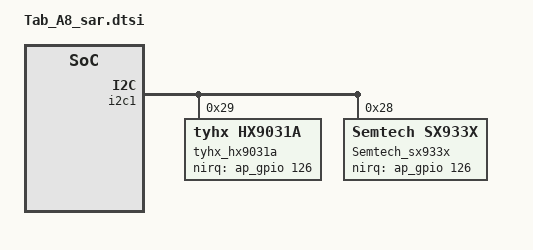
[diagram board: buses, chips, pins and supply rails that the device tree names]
/* I2C device */
&i2c1{
/*Tab A8 code for SR-AX6300-01-81 by mayuhang at 2021/8/12 start*/
    tyhx_hx9031a@29 {
        compatible = "tyhx,hx9031a";
        reg = <0x29>;
        interrupt-parent = <&ap_gpio>;
        //interrupts = <126 0>;
        tyhx,nirq-gpio = <&ap_gpio 126 0x00>;
        tyhx,channel-flag = <0x07>;
    };
/*Tab A8 code for SR-AX6300-01-81 by mayuhang at 2021/8/12 end*/
/*Tab A8 code for SR-AX6300-01-66|AX6300DEV-4155 by mayuhang|lichang at 2022/11/29 start*/
    Semtech_sx933x@28 {
        compatible = "Semtech,sx933x";
        reg = <0x28>;
        interrupt-parent = <&ap_gpio>;
        //interrupts = <126 0>;
        Semtech,nirq-gpio = <&ap_gpio 126 0x00>;
        /*use PH3/4 as the reference sensor
        set it to 0xff if the ref-phases-x is not used*/
        Semtech,ref-phases-a = <0>;
        Semtech,ref-phases-b = <4>;
        Semtech,reg-num = <85>;
        Semtech,reg-init = <
        0x4004 0x00000070
        0x4008 0x00000000
        0x4054 0x00000400
        0x42C0 0x08000000
        0x42C4 0x0000003F
        0x800C 0x00000000
        0x8010 0x00000000
        0x8014 0x00000000
        0x8018 0x00000000
        0x801C 0x00000031
        0x8020 0x001F001F
        0x8028 0x3FFE82DA
        0x802C 0x10000A66
        0x8030 0x3FF78265
        0x8034 0x10000A66
        0x8038 0x3FBF82C5
        0x803C 0x10000A66
        0x8040 0x3DFF8268
        0x8044 0x10000A76
        0x8048 0x2FFF834B
        0x804C 0x00000000
        0x8050 0x00000000
        0x8054 0x1652FF00
        0x8058 0x20630030
        0x805C 0x00005300
        0x8060 0x00000000
        0x8064 0x00000000
        0x8068 0x00000000
        0x806C 0x00000000
        0x8070 0x00000000
        0x8074 0x10322F05
        0x8078 0x20630030
        0x807C 0x00005300
        0x8080 0x00000000
        0x8084 0x00000000
        0x8088 0x00000000
        0x808C 0x1E001E00
        0x8090 0x00010000
        0x8094 0x10321C05
        0x8098 0x20630030
        0x809C 0x00005300
        0x80A0 0x00000000
        0x80A4 0x00000000
        0x80A8 0x00000000
        0x80AC 0x00030003
        0x80B0 0x00000000
        0x80B4 0x10321A00
        0x80B8 0x20630030
        0x80BC 0x00005300
        0x80C0 0x00000000
        0x80C4 0x00000000
        0x80C8 0x00000000
        0x80CC 0x001B001B
        0x80D0 0x00020000
        0x80D4 0x1652FF05
        0x80D8 0x20630030
        0x80DC 0x00005300
        0x80E0 0x00000000
        0x80E4 0x00000000
        0x80E8 0x00000000
        0x80EC 0x00000000
        0x80F0 0x00000000
        0x80F4 0x00000000
        0x80F8 0x00000000
        0x80FC 0x00000000
        0x8100 0x00000000
        0x8104 0x00000000
        0x8108 0x00000000
        0x810C 0x00000000
        0x8110 0x00000000
        0x8124 0x04000008
        0x8128 0x0400000C
        0x812C 0x00000000
        0x8130 0x00000000
        0x8134 0x00000000
        0x8138 0x00000000
        0x813C 0x00000000
        0x8140 0x00000000
        0x8144 0x00000000
        0x8148 0x00000000
        0x814C 0x00000000
        0x81A4 0x01D00008
        0x4280 0x0000000F
        0x8024 0x10000A76
        0x4280 0x0000000E>;
    };
};
/*Tab A8 code for SR-AX6300-01-66|AX6300DEV-4155 by mayuhang|lichang at 2022/11/29 end*/
